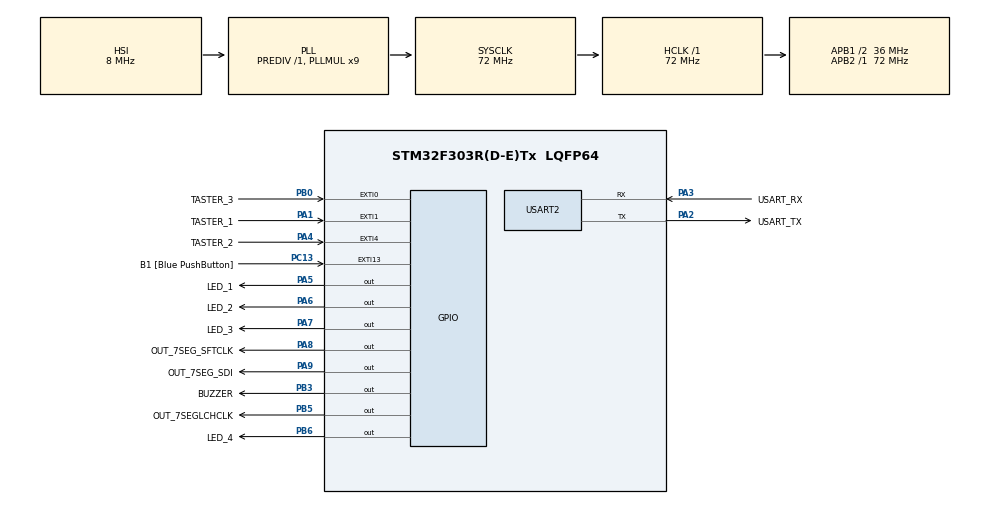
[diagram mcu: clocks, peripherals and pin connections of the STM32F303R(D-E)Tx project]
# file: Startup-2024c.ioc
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FREERTOS.BinarySemaphores01=ledSemaphore,Static,ledSemaphoreControlBlock;buzzerSemaphore,Static,buzzerSemaphoreControlBlock
FREERTOS.Tasks01=defaultTask,8,128,StartDefaultTask,Default,NULL,Static,defaultTaskBuffer,defaultTaskControlBlock;displayUpdate,37,128,DisplayUpdateTask,As external,NULL,Static,displayUpdateBuffer,displayUpdateControlBlock;stopwatch,40,128,StopwatchTask,As external,NULL,Static,stopwatchBuffer,stopwatchControlBlock;timer,40,128,TimerTask,As external,NULL,Static,timerTaskBuffer,timerTaskControlBlock;stateEvent,25,128,StateEventTask,As external,NULL,Static,stateEventBuffer,stateEventControlBlock;buzzer,9,128,BuzzerTask,As external,NULL,Static,buzzerBuffer,buzzerControlBlock;taster,39,128,TasterTask,As external,NULL,Static,tasterBuffer,tasterControlBlock
FREERTOS.configUSE_NEWLIB_REENTRANT=1
Mcu.Family=STM32F3
Mcu.Name=STM32F303R(D-E)Tx
Mcu.Package=LQFP64
NVIC.EXTI0_IRQn=true\:5\:0\:false\:false\:true\:true\:true\:true\:true
NVIC.EXTI15_10_IRQn=true\:5\:0\:false\:false\:true\:true\:true\:true\:true
NVIC.EXTI1_IRQn=true\:5\:0\:false\:false\:true\:true\:true\:true\:true
NVIC.EXTI4_IRQn=true\:5\:0\:false\:false\:true\:true\:true\:true\:true
NVIC.PriorityGroup=NVIC_PRIORITYGROUP_4
NVIC.TIM1_UP_TIM16_IRQn=true\:15\:0\:false\:false\:true\:false\:false\:true\:true
NVIC.TimeBase=TIM1_UP_TIM16_IRQn
NVIC.TimeBaseIP=TIM1
PA1.GPIO_Label=TASTER_1
PA1.GPIO_ModeDefaultEXTI=GPIO_MODE_IT_RISING_FALLING
PA1.GPIO_PuPd=GPIO_PULLUP
PA1.Signal=GPXTI1
PA13.GPIO_Label=TMS
PA13.Mode=Serial_Wire
PA13.Signal=SYS_JTMS-SWDIO
PA14.GPIO_Label=TCK
PA14.Mode=Serial_Wire
PA14.Signal=SYS_JTCK-SWCLK
PA2.GPIO_Label=USART_TX
PA2.GPIO_Mode=GPIO_MODE_AF_PP
PA2.GPIO_PuPd=GPIO_NOPULL
PA2.GPIO_Speed=GPIO_SPEED_FREQ_LOW
PA2.Mode=Asynchronous
PA2.Signal=USART2_TX
PA3.GPIO_Label=USART_RX
PA3.GPIO_Mode=GPIO_MODE_AF_PP
PA3.GPIO_PuPd=GPIO_NOPULL
PA3.GPIO_Speed=GPIO_SPEED_FREQ_LOW
PA3.Mode=Asynchronous
PA3.Signal=USART2_RX
PA4.GPIO_Label=TASTER_2
PA4.GPIO_ModeDefaultEXTI=GPIO_MODE_IT_RISING_FALLING
PA4.GPIO_PuPd=GPIO_PULLUP
PA4.Signal=GPXTI4
PA5.GPIO_Label=LED_1
PA5.GPIO_Mode=GPIO_MODE_OUTPUT_PP
PA5.GPIO_ModeDefaultOutputPP=GPIO_MODE_OUTPUT_PP
PA5.GPIO_PuPd=GPIO_NOPULL
PA5.GPIO_Speed=GPIO_SPEED_FREQ_LOW
PA5.PinState=GPIO_PIN_SET
PA5.Signal=GPIO_Output
PA6.GPIO_Label=LED_2
PA6.PinState=GPIO_PIN_SET
PA6.Signal=GPIO_Output
PA7.GPIO_Label=LED_3
PA7.PinState=GPIO_PIN_SET
PA7.Signal=GPIO_Output
PA8.GPIO_Label=OUT_7SEG_SFTCLK
PA8.GPIO_Speed=GPIO_SPEED_FREQ_HIGH
PA8.Signal=GPIO_Output
PA9.GPIO_Label=OUT_7SEG_SDI
PA9.GPIO_Speed=GPIO_SPEED_FREQ_HIGH
PA9.Signal=GPIO_Output
PB0.GPIO_Label=TASTER_3
PB0.GPIO_ModeDefaultEXTI=GPIO_MODE_IT_RISING_FALLING
PB0.GPIO_PuPd=GPIO_PULLUP
PB0.Signal=GPXTI0
PB3.GPIO_Label=BUZZER
PB3.PinState=GPIO_PIN_SET
PB3.Signal=GPIO_Output
PB5.GPIO_Label=OUT_7SEGLCHCLK
PB5.GPIO_Speed=GPIO_SPEED_FREQ_HIGH
PB5.Signal=GPIO_Output
PB6.GPIO_Label=LED_4
PB6.PinState=GPIO_PIN_SET
PB6.Signal=GPIO_Output
PC13.GPIO_Label=B1 [Blue PushButton]
PC13.GPIO_ModeDefaultEXTI=GPIO_MODE_IT_FALLING
PC13.Signal=GPXTI13
PC14-OSC32_IN.Mode=LSE-External-Oscillator
PC14-OSC32_IN.Signal=RCC_OSC32_IN
PC15-OSC32_OUT.Mode=LSE-External-Oscillator
PC15-OSC32_OUT.Signal=RCC_OSC32_OUT
PF0-OSC_IN.Mode=HSE-External-Clock-Source
PF0-OSC_IN.Signal=RCC_OSC_IN
PF1-OSC_OUT.Signal=RCC_OSC_OUT
ProjectManager.HeapSize=0x200
ProjectManager.StackSize=0x400
ProjectManager.TargetToolchain=STM32CubeIDE
RCC.AHBFreq_Value=72000000
RCC.APB1CLKDivider=RCC_HCLK_DIV2
RCC.APB1Freq_Value=36000000
RCC.APB1TimFreq_Value=72000000
RCC.APB2Freq_Value=72000000
RCC.APB2TimFreq_Value=72000000
RCC.CortexFreq_Value=72000000
RCC.HCLKFreq_Value=72000000
RCC.HSE_VALUE=8000000
RCC.HSI_VALUE=8000000
RCC.PLLM=8
RCC.PLLMUL=RCC_PLL_MUL9
RCC.PLLN=336
RCC.PLLP=RCC_PLLP_DIV4
RCC.PLLQ=7
RCC.RCC_PLLsource_Clock_Source_FROM_HSE=RCC_HSE_PREDIV_DIV2
RCC.SYSCLKFreq_VALUE=72000000
RCC.SYSCLKSourceVirtual=RCC_SYSCLKSOURCE_PLLCLK
RCC.USBFreq_Value=72000000
USART2.VirtualMode-Asynchronous=VM_ASYNC
VP_FREERTOS_VS_CMSIS_V2.Mode=CMSIS_V2
VP_SYS_VS_tim1.Mode=TIM1
board=NUCLEO-F303RE

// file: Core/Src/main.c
/* USER CODE BEGIN Header */
/**
 ******************************************************************************
 * @file           : main.c
 * @brief          : Main program body
 ******************************************************************************
 * @attention
 *
 * Copyright (c) 2023 STMicroelectronics.
 * All rights reserved.
 *
 * This software is licensed under terms that can be found in the LICENSE file
 * in the root directory of this software component.
 * If no LICENSE file comes with this software, it is provided AS-IS.
 *
 ******************************************************************************
 */
/* USER CODE END Header */
#include "main.h"
#include "cmsis_os.h"

/* USER CODE BEGIN Includes */

// The StateEvent library contains all the includes we need
#include "StateEvent.h"

// Event-Steuerung
#include "Stopwatch.h"
#include "Timer.h"

// Treiber
#include "Taster_Treiber.h"
#include "Buzzer_Treiber.h"
#include "Display_Treiber.h"
#include "LED_Treiber.h"
#include "Seg_Driver.h"

/* USER CODE END Includes */

typedef StaticTask_t osStaticThreadDef_t;
typedef StaticSemaphore_t osStaticSemaphoreDef_t;

UART_HandleTypeDef huart2;

/* Definitions for defaultTask */
osThreadId_t defaultTaskHandle;
uint32_t defaultTaskBuffer[ 128 ];
osStaticThreadDef_t defaultTaskControlBlock;
const osThreadAttr_t defaultTask_attributes = {
  .name = "defaultTask",
  .cb_mem = &defaultTaskControlBlock,
  .cb_size = sizeof(defaultTaskControlBlock),
  .stack_mem = &defaultTaskBuffer[0],
  .stack_size = sizeof(defaultTaskBuffer),
  .priority = (osPriority_t) osPriorityLow,
};
/* Definitions for displayUpdate */
osThreadId_t displayUpdateHandle;
uint32_t displayUpdateBuffer[ 128 ];
osStaticThreadDef_t displayUpdateControlBlock;
const osThreadAttr_t displayUpdate_attributes = {
  .name = "displayUpdate",
  .cb_mem = &displayUpdateControlBlock,
  .cb_size = sizeof(displayUpdateControlBlock),
  .stack_mem = &displayUpdateBuffer[0],
  .stack_size = sizeof(displayUpdateBuffer),
  .priority = (osPriority_t) osPriorityAboveNormal5,
};
/* Definitions for stopwatch */
osThreadId_t stopwatchHandle;
uint32_t stopwatchBuffer[ 128 ];
osStaticThreadDef_t stopwatchControlBlock;
const osThreadAttr_t stopwatch_attributes = {
  .name = "stopwatch",
  .cb_mem = &stopwatchControlBlock,
  .cb_size = sizeof(stopwatchControlBlock),
  .stack_mem = &stopwatchBuffer[0],
  .stack_size = sizeof(stopwatchBuffer),
  .priority = (osPriority_t) osPriorityHigh,
};
/* Definitions for timer */
osThreadId_t timerHandle;
uint32_t timerTaskBuffer[ 128 ];
osStaticThreadDef_t timerTaskControlBlock;
const osThreadAttr_t timer_attributes = {
  .name = "timer",
  .cb_mem = &timerTaskControlBlock,
  .cb_size = sizeof(timerTaskControlBlock),
  .stack_mem = &timerTaskBuffer[0],
  .stack_size = sizeof(timerTaskBuffer),
  .priority = (osPriority_t) osPriorityHigh,
};
/* Definitions for stateEvent */
osThreadId_t stateEventHandle;
uint32_t stateEventBuffer[ 128 ];
osStaticThreadDef_t stateEventControlBlock;
const osThreadAttr_t stateEvent_attributes = {
  .name = "stateEvent",
  .cb_mem = &stateEventControlBlock,
  .cb_size = sizeof(stateEventControlBlock),
  .stack_mem = &stateEventBuffer[0],
  .stack_size = sizeof(stateEventBuffer),
  .priority = (osPriority_t) osPriorityNormal1,
};
/* Definitions for buzzer */
osThreadId_t buzzerHandle;
uint32_t buzzerBuffer[ 128 ];
osStaticThreadDef_t buzzerControlBlock;
const osThreadAttr_t buzzer_attributes = {
  .name = "buzzer",
  .cb_mem = &buzzerControlBlock,
  .cb_size = sizeof(buzzerControlBlock),
  .stack_mem = &buzzerBuffer[0],
  .stack_size = sizeof(buzzerBuffer),
  .priority = (osPriority_t) osPriorityLow1,
};
/* Definitions for taster */
osThreadId_t tasterHandle;
uint32_t tasterBuffer[ 128 ];
osStaticThreadDef_t tasterControlBlock;
const osThreadAttr_t taster_attributes = {
  .name = "taster",
  .cb_mem = &tasterControlBlock,
  .cb_size = sizeof(tasterControlBlock),
  .stack_mem = &tasterBuffer[0],
  .stack_size = sizeof(tasterBuffer),
  .priority = (osPriority_t) osPriorityAboveNormal7,
};
/* Definitions for ledSemaphore */
osSemaphoreId_t ledSemaphoreHandle;
osStaticSemaphoreDef_t ledSemaphoreControlBlock;
const osSemaphoreAttr_t ledSemaphore_attributes = {
  .name = "ledSemaphore",
  .cb_mem = &ledSemaphoreControlBlock,
  .cb_size = sizeof(ledSemaphoreControlBlock),
};
/* Definitions for buzzerSemaphore */
osSemaphoreId_t buzzerSemaphoreHandle;
osStaticSemaphoreDef_t buzzerSemaphoreControlBlock;
const osSemaphoreAttr_t buzzerSemaphore_attributes = {
  .name = "buzzerSemaphore",
  .cb_mem = &buzzerSemaphoreControlBlock,
  .cb_size = sizeof(buzzerSemaphoreControlBlock),
};

void SystemClock_Config(void);
static void MX_GPIO_Init(void);
static void MX_USART2_UART_Init(void);
void StartDefaultTask(void *argument);
extern void DisplayUpdateTask(void *argument);
extern void StopwatchTask(void *argument);
extern void TimerTask(void *argument);
extern void StateEventTask(void *argument);
extern void BuzzerTask(void *argument);
extern void TasterTask(void *argument);

int main(void)
{

  /* MCU Configuration--------------------------------------------------------*/

  /* Reset of all peripherals, Initializes the Flash interface and the Systick. */
  HAL_Init();

  /* Configure the system clock */
  SystemClock_Config();

  /* Initialize all configured peripherals */
  MX_GPIO_Init();
  MX_USART2_UART_Init();

  /* Init scheduler */
  osKernelInitialize();

  /* Create the semaphores(s) */
  /* creation of ledSemaphore */
  ledSemaphoreHandle = osSemaphoreNew(1, 1, &ledSemaphore_attributes);

  /* creation of buzzerSemaphore */
  buzzerSemaphoreHandle = osSemaphoreNew(1, 1, &buzzerSemaphore_attributes);

  /* USER CODE BEGIN RTOS_SEMAPHORES */

  // Save the semaphore handles to a global variable
  ledSemaphoreHandleId = ledSemaphoreHandle;
  buzzerSemaphoreHandleId = buzzerSemaphoreHandle;

  /* USER CODE END RTOS_SEMAPHORES */

  /* Create the thread(s) */
  /* creation of defaultTask */
  defaultTaskHandle = osThreadNew(StartDefaultTask, NULL, &defaultTask_attributes);

  /* creation of displayUpdate */
  displayUpdateHandle = osThreadNew(DisplayUpdateTask, NULL, &displayUpdate_attributes);

  /* creation of stopwatch */
  stopwatchHandle = osThreadNew(StopwatchTask, NULL, &stopwatch_attributes);

  /* creation of timer */
  timerHandle = osThreadNew(TimerTask, NULL, &timer_attributes);

  /* creation of stateEvent */
  stateEventHandle = osThreadNew(StateEventTask, NULL, &stateEvent_attributes);

  /* creation of buzzer */
  buzzerHandle = osThreadNew(BuzzerTask, NULL, &buzzer_attributes);

  /* creation of taster */
  tasterHandle = osThreadNew(TasterTask, NULL, &taster_attributes);

  /* Start scheduler */
  osKernelStart();
  /* We should never get here as control is now taken by the scheduler */
  /* Infinite loop */
  while (1)
  {

  }
}

void SystemClock_Config(void)
{
  RCC_OscInitTypeDef RCC_OscInitStruct = {0};
  RCC_ClkInitTypeDef RCC_ClkInitStruct = {0};
  RCC_PeriphCLKInitTypeDef PeriphClkInit = {0};

  /** Initializes the RCC Oscillators according to the specified parameters
  * in the RCC_OscInitTypeDef structure.
  */
  RCC_OscInitStruct.OscillatorType = RCC_OSCILLATORTYPE_HSI;
  RCC_OscInitStruct.HSIState = RCC_HSI_ON;
  RCC_OscInitStruct.HSICalibrationValue = RCC_HSICALIBRATION_DEFAULT;
  RCC_OscInitStruct.PLL.PLLState = RCC_PLL_ON;
  RCC_OscInitStruct.PLL.PLLSource = RCC_PLLSOURCE_HSI;
  RCC_OscInitStruct.PLL.PLLMUL = RCC_PLL_MUL9;
  RCC_OscInitStruct.PLL.PREDIV = RCC_PREDIV_DIV1;
  if (HAL_RCC_OscConfig(&RCC_OscInitStruct) != HAL_OK)
  {
    Error_Handler();
  }

  /** Initializes the CPU, AHB and APB buses clocks
  */
  RCC_ClkInitStruct.ClockType = RCC_CLOCKTYPE_HCLK|RCC_CLOCKTYPE_SYSCLK
                              |RCC_CLOCKTYPE_PCLK1|RCC_CLOCKTYPE_PCLK2;
  RCC_ClkInitStruct.SYSCLKSource = RCC_SYSCLKSOURCE_PLLCLK;
  RCC_ClkInitStruct.AHBCLKDivider = RCC_SYSCLK_DIV1;
  RCC_ClkInitStruct.APB1CLKDivider = RCC_HCLK_DIV2;
  RCC_ClkInitStruct.APB2CLKDivider = RCC_HCLK_DIV1;

  if (HAL_RCC_ClockConfig(&RCC_ClkInitStruct, FLASH_LATENCY_2) != HAL_OK)
  {
    Error_Handler();
  }
  PeriphClkInit.PeriphClockSelection = RCC_PERIPHCLK_USART2;
  PeriphClkInit.Usart2ClockSelection = RCC_USART2CLKSOURCE_PCLK1;
  if (HAL_RCCEx_PeriphCLKConfig(&PeriphClkInit) != HAL_OK)
  {
    Error_Handler();
  }
}

static void MX_USART2_UART_Init(void)
{

  huart2.Instance = USART2;
  huart2.Init.BaudRate = 38400;
  huart2.Init.WordLength = UART_WORDLENGTH_8B;
  huart2.Init.StopBits = UART_STOPBITS_1;
  huart2.Init.Parity = UART_PARITY_NONE;
  huart2.Init.Mode = UART_MODE_TX_RX;
  huart2.Init.HwFlowCtl = UART_HWCONTROL_NONE;
  huart2.Init.OverSampling = UART_OVERSAMPLING_16;
  huart2.Init.OneBitSampling = UART_ONE_BIT_SAMPLE_DISABLE;
  huart2.AdvancedInit.AdvFeatureInit = UART_ADVFEATURE_NO_INIT;
  if (HAL_UART_Init(&huart2) != HAL_OK)
  {
    Error_Handler();
  }

}

static void MX_GPIO_Init(void)
{
  GPIO_InitTypeDef GPIO_InitStruct = {0};

  /* GPIO Ports Clock Enable */
  __HAL_RCC_GPIOC_CLK_ENABLE();
  __HAL_RCC_GPIOF_CLK_ENABLE();
  __HAL_RCC_GPIOA_CLK_ENABLE();
  __HAL_RCC_GPIOB_CLK_ENABLE();

  /*Configure GPIO pin Output Level */
  HAL_GPIO_WritePin(GPIOA, LED_1_Pin|LED_2_Pin|LED_3_Pin, GPIO_PIN_SET);

  /*Configure GPIO pin Output Level */
  HAL_GPIO_WritePin(GPIOA, OUT_7SEG_SFTCLK_Pin|OUT_7SEG_SDI_Pin, GPIO_PIN_RESET);

  /*Configure GPIO pin Output Level */
  HAL_GPIO_WritePin(GPIOB, BUZZER_Pin|LED_4_Pin, GPIO_PIN_SET);

  /*Configure GPIO pin Output Level */
  HAL_GPIO_WritePin(OUT_7SEGLCHCLK_GPIO_Port, OUT_7SEGLCHCLK_Pin, GPIO_PIN_RESET);

  /*Configure GPIO pin : B1_Pin */
  GPIO_InitStruct.Pin = B1_Pin;
  GPIO_InitStruct.Mode = GPIO_MODE_IT_FALLING;
  GPIO_InitStruct.Pull = GPIO_NOPULL;
  HAL_GPIO_Init(B1_GPIO_Port, &GPIO_InitStruct);

  /*Configure GPIO pins : TASTER_1_Pin TASTER_2_Pin */
  GPIO_InitStruct.Pin = TASTER_1_Pin|TASTER_2_Pin;
  GPIO_InitStruct.Mode = GPIO_MODE_IT_RISING_FALLING;
  GPIO_InitStruct.Pull = GPIO_PULLUP;
  HAL_GPIO_Init(GPIOA, &GPIO_InitStruct);

  /*Configure GPIO pins : LED_1_Pin LED_2_Pin LED_3_Pin */
  GPIO_InitStruct.Pin = LED_1_Pin|LED_2_Pin|LED_3_Pin;
  GPIO_InitStruct.Mode = GPIO_MODE_OUTPUT_PP;
  GPIO_InitStruct.Pull = GPIO_NOPULL;
  GPIO_InitStruct.Speed = GPIO_SPEED_FREQ_LOW;
  HAL_GPIO_Init(GPIOA, &GPIO_InitStruct);

  /*Configure GPIO pin : TASTER_3_Pin */
  GPIO_InitStruct.Pin = TASTER_3_Pin;
  GPIO_InitStruct.Mode = GPIO_MODE_IT_RISING_FALLING;
  GPIO_InitStruct.Pull = GPIO_PULLUP;
  HAL_GPIO_Init(TASTER_3_GPIO_Port, &GPIO_InitStruct);

  /*Configure GPIO pins : OUT_7SEG_SFTCLK_Pin OUT_7SEG_SDI_Pin */
  GPIO_InitStruct.Pin = OUT_7SEG_SFTCLK_Pin|OUT_7SEG_SDI_Pin;
  GPIO_InitStruct.Mode = GPIO_MODE_OUTPUT_PP;
  GPIO_InitStruct.Pull = GPIO_NOPULL;
  GPIO_InitStruct.Speed = GPIO_SPEED_FREQ_HIGH;
  HAL_GPIO_Init(GPIOA, &GPIO_InitStruct);

  /*Configure GPIO pins : BUZZER_Pin LED_4_Pin */
  GPIO_InitStruct.Pin = BUZZER_Pin|LED_4_Pin;
  GPIO_InitStruct.Mode = GPIO_MODE_OUTPUT_PP;
  GPIO_InitStruct.Pull = GPIO_NOPULL;
  GPIO_InitStruct.Speed = GPIO_SPEED_FREQ_LOW;
  HAL_GPIO_Init(GPIOB, &GPIO_InitStruct);

  /*Configure GPIO pin : OUT_7SEGLCHCLK_Pin */
  GPIO_InitStruct.Pin = OUT_7SEGLCHCLK_Pin;
  GPIO_InitStruct.Mode = GPIO_MODE_OUTPUT_PP;
  GPIO_InitStruct.Pull = GPIO_NOPULL;
  GPIO_InitStruct.Speed = GPIO_SPEED_FREQ_HIGH;
  HAL_GPIO_Init(OUT_7SEGLCHCLK_GPIO_Port, &GPIO_InitStruct);

  /* EXTI interrupt init*/
  HAL_NVIC_SetPriority(EXTI0_IRQn, 5, 0);
  HAL_NVIC_EnableIRQ(EXTI0_IRQn);

  HAL_NVIC_SetPriority(EXTI1_IRQn, 5, 0);
  HAL_NVIC_EnableIRQ(EXTI1_IRQn);

  HAL_NVIC_SetPriority(EXTI4_IRQn, 5, 0);
  HAL_NVIC_EnableIRQ(EXTI4_IRQn);

  HAL_NVIC_SetPriority(EXTI15_10_IRQn, 5, 0);
  HAL_NVIC_EnableIRQ(EXTI15_10_IRQn);

}

void StartDefaultTask(void *argument)
{
  /* USER CODE BEGIN 5 */

  while (true)
  {
    // The default task can not be deleted for some reason so we just let it sleep forever ;)
    osDelay(1234);
  }

  /* USER CODE END 5 */
}

void HAL_TIM_PeriodElapsedCallback(TIM_HandleTypeDef *htim)
{
  if (htim->Instance == TIM1) {
    HAL_IncTick();
  }
}

void Error_Handler(void)
{
  __disable_irq();
  while (1)
  {
  }
}
